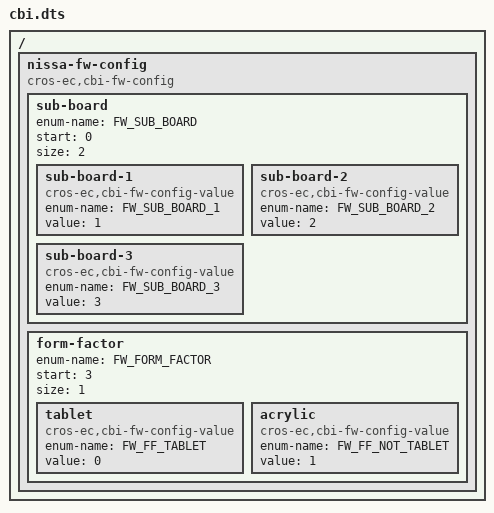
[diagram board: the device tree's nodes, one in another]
/* Copyright 2022 The Chromium OS Authors. All rights reserved.
 * Use of this source code is governed by a BSD-style license that can be
 * found in the LICENSE file.
 */

/ {
	nissa-fw-config {
		compatible = "cros-ec,cbi-fw-config";

		/*
		 * FW_CONFIG field to indicate which sub-board
		 * is attached.
		 */
		sub-board {
			enum-name = "FW_SUB_BOARD";
			start = <0>;
			size = <2>;

			sub-board-1 {
				compatible = "cros-ec,cbi-fw-config-value";
				enum-name = "FW_SUB_BOARD_1";
				value = <1>;
			};
			sub-board-2 {
				compatible = "cros-ec,cbi-fw-config-value";
				enum-name = "FW_SUB_BOARD_2";
				value = <2>;
			};
			sub-board-3 {
				compatible = "cros-ec,cbi-fw-config-value";
				enum-name = "FW_SUB_BOARD_3";
				value = <3>;
			};
		};

		/*
		 * FW_CONFIG field to enable fan or not.
		 */
		form-factor {
			enum-name = "FW_FAN";
			start = <2>;
			size = <1>;

			tablet {
				compatible = "cros-ec,cbi-fw-config-value";
				enum-name = "FW_FAN_NOT_PRESENT";
				value = <0>;
			};
			acrylic {
				compatible = "cros-ec,cbi-fw-config-value";
				enum-name = "FW_FAN_PRESENT";
				value = <1>;
			};
		};

		/*
		 * FW_CONFIG field to set form factor based config.
		 */
		form-factor {
			enum-name = "FW_FORM_FACTOR";
			start = <3>;
			size = <1>;

			tablet {
				compatible = "cros-ec,cbi-fw-config-value";
				enum-name = "FW_FF_TABLET";
				value = <0>;
			};
			acrylic {
				compatible = "cros-ec,cbi-fw-config-value";
				enum-name = "FW_FF_NOT_TABLET";
				value = <1>;
			};
		};
	};
};
